# ESP32-C6 register map
Vendor: ESPRESSIF SYSTEMS (SHANGHAI) CO., LTD.; Series: ESP32 C-Series; File version: 12
CPU: RV32IMAC r0p0, little endian, no MPU, no FPU, 0 interrupt priority bits
Address unit: 32 bits
Registers are 32-bit, read-write, reset 0x0 unless marked. A register's access mark holds for its fields unless they carry their own. Offsets are from the block's base; [hi:lo] are bit positions; lines under a group give offsets from that group; {n}, {i} and the like mark numbered series.

## SYSTIMER — System Timer
Base 0x6000A000
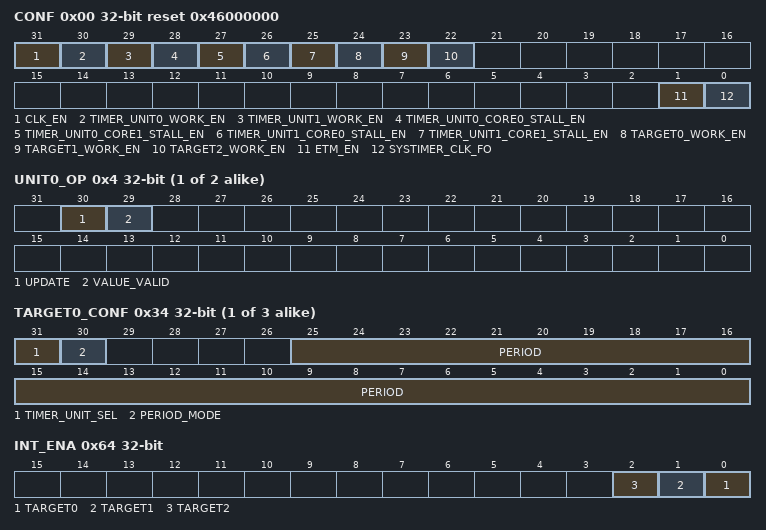
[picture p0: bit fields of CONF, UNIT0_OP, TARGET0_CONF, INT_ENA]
0x00 CONF reset 0x46000000 — Configure system timer clock
  [31] CLK_EN — register file clk gating
  [30] TIMER_UNIT0_WORK_EN — timer unit0 work enable
  [29] TIMER_UNIT1_WORK_EN — timer unit1 work enable
  [28] TIMER_UNIT0_CORE0_STALL_EN — If timer unit0 is stalled when core0 stalled
  [27] TIMER_UNIT0_CORE1_STALL_EN — If timer unit0 is stalled when core1 stalled
  [26] TIMER_UNIT1_CORE0_STALL_EN — If timer unit1 is stalled when core0 stalled
  [25] TIMER_UNIT1_CORE1_STALL_EN — If timer unit1 is stalled when core1 stalled
  [24] TARGET0_WORK_EN — target0 work enable
  [23] TARGET1_WORK_EN — target1 work enable
  [22] TARGET2_WORK_EN — target2 work enable
  [1] ETM_EN — enable systimer's etm task and event
  [0] SYSTIMER_CLK_FO — systimer clock force on
{0x4+4i} UNIT{i}_OP (i=0..1) access per field — system timer unit{i} value update register
  [30] UPDATE wo — update timer_unit0
  [29] VALUE_VALID ro — timer value is sync and valid
0x0C UNIT0LOAD group — Cluster UNIT%sLOAD, containing UNIT?_LOAD_HI, UNIT?_LOAD_LO
  0x00 HI — system timer unit0 value high load register
    [19:0] LOAD_HI — timer unit0 load high 20 bits
  0x04 LO — system timer unit0 value low load register
    [31:0] LOAD_LO — timer unit0 load low 32 bits
0x14 UNIT1LOAD group — Cluster UNIT%sLOAD, containing UNIT?_LOAD_HI, UNIT?_LOAD_LO
  0x00 HI — system timer unit0 value high load register
    [19:0] LOAD_HI — timer unit0 load high 20 bits
  0x04 LO — system timer unit0 value low load register
    [31:0] LOAD_LO — timer unit0 load low 32 bits
{0x1C+8i} TRGT{i} group (i=0..2) — Cluster TRGT%s, containing TARGET?_HI, TARGET?_LO
  0x00 HI — system timer comp0 value high register
    [19:0] HI — timer taget0 high 20 bits
  0x04 LO — system timer comp0 value low register
    [31:0] LO — timer taget0 low 32 bits
{0x34+4i} TARGET{i}_CONF (i=0..2) — system timer comp{i} target mode register
  [31] TIMER_UNIT_SEL — select which unit to compare
  [30] PERIOD_MODE — Set target0 to period mode
  [25:0] PERIOD — target0 period
0x40 UNIT0_VALUE group — Cluster UNIT%s_VALUE, containing UNIT?_VALUE_HI, UNIT?_VALUE_LO
  0x00 HI ro — system timer unit0 value high register
    [19:0] VALUE_HI — timer read value high 20bits
  0x04 LO ro — system timer unit0 value low register
    [31:0] VALUE_LO — timer read value low 32bits
0x48 UNIT1_VALUE group — Cluster UNIT%s_VALUE, containing UNIT?_VALUE_HI, UNIT?_VALUE_LO
  0x00 HI ro — system timer unit0 value high register
    [19:0] VALUE_HI — timer read value high 20bits
  0x04 LO ro — system timer unit0 value low register
    [31:0] VALUE_LO — timer read value low 32bits
{0x50+4i} COMP{i}_LOAD (i=0..2) wo — system timer comp{i} conf sync register
  [0] LOAD — timer comp0 sync enable signal
{0x5C+4i} UNIT{i}_LOAD (i=0..1) wo — system timer unit{i} conf sync register
  [0] LOAD — timer unit0 sync enable signal
0x64 INT_ENA — systimer interrupt enable register
  [n] TARGET{n} (n=0..2) — interupt{n} enable
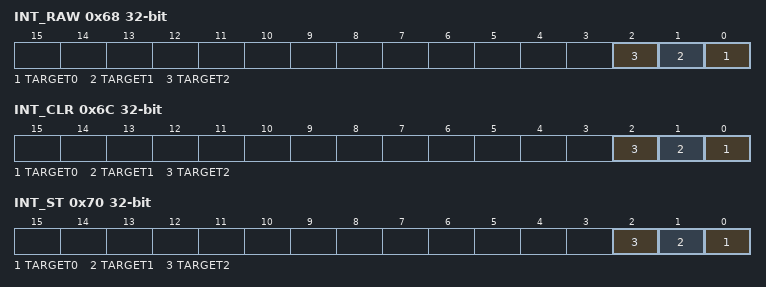
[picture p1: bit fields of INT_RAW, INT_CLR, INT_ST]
0x68 INT_RAW — systimer interrupt raw register
  [n] TARGET{n} (n=0..2) — interupt{n} raw
0x6C INT_CLR wo — systimer interrupt clear register
  [n] TARGET{n} (n=0..2) write-1-clears — interupt{n} clear
0x70 INT_ST ro — systimer interrupt status register
  [n] TARGET{n} (n=0..2) — interupt{n} status
{0x74+8i} REAL_TARGET{i} group (i=0..2) — Cluster REAL_TARGET%s, containing REAL_TARGET?_LO, REAL_TARGET?_HI
  0x00 LO ro — system timer comp0 actual target value low register
    [31:0] LO_RO — actual target value value low 32bits
  0x04 HI ro — system timer comp0 actual target value high register
    [19:0] HI_RO — actual target value value high 20bits
0xFC DATE — system timer version control register
